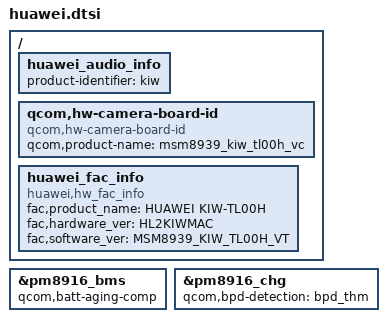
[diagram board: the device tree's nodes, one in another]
#include "../kiwi/huawei.dtsi"
#include "../kiwi/huawei-camera-vc.dtsi"
#include "../kiwi/huawei-sensors-vc.dtsi"
#include "../kiwi/huawei-rmtfs.dtsi"

/ {
	huawei_audio_info {
		product-identifier = "kiw";
	};

	qcom,hw-camera-board-id {
		compatible = "qcom,hw-camera-board-id";
		qcom,product-name = "msm8939_kiw_tl00h_vc";
	};

	huawei_fac_info {
		compatible = "huawei,hw_fac_info";
		fac,product_name = "HUAWEI KIW-TL00H";
		fac,hardware_ver = "HL2KIWMAC";
		fac,software_ver = "MSM8939_KIW_TL00H_VT";
		status = "ok";
	};
};

&pm8916_bms {
	status = "ok";
	/* kiwi: count charge cycles (every SOC rise added up, one cycle per 100 %), kept in
	 * the PMIC BMS storage registers so the count survives reboots and reflashes. The
	 * driver only counts; it does not use the count for the SOC calculation. */
	qcom,batt-aging-comp;
};

&pm8916_chg {
	qcom,bpd-detection = "bpd_thm";
};
